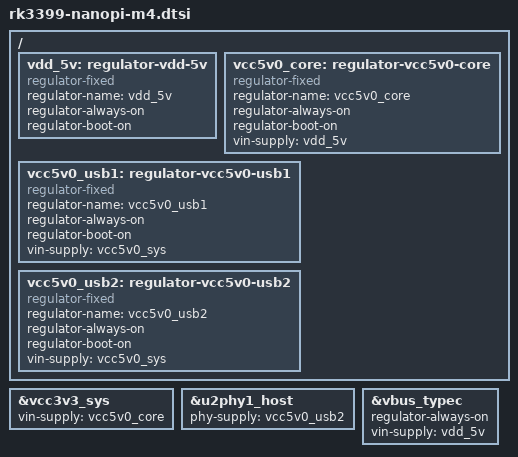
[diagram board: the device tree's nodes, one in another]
// SPDX-License-Identifier: (GPL-2.0+ OR MIT)
/*
 * FriendlyElec NanoPi M4 board device tree source
 *
 * Copyright (c) 2018 FriendlyElec Computer Tech. Co., Ltd.
 * (http://www.friendlyarm.com)
 *
 * Copyright (c) 2018 Collabora Ltd.
 * Copyright (c) 2019 Arm Ltd.
 */

/dts-v1/;

#include "rk3399-nanopi4.dtsi"

/ {
	vdd_5v: regulator-vdd-5v {
		compatible = "regulator-fixed";
		regulator-name = "vdd_5v";
		regulator-always-on;
		regulator-boot-on;
	};

	vcc5v0_core: regulator-vcc5v0-core {
		compatible = "regulator-fixed";
		regulator-name = "vcc5v0_core";
		regulator-always-on;
		regulator-boot-on;
		vin-supply = <&vdd_5v>;
	};

	vcc5v0_usb1: regulator-vcc5v0-usb1 {
		compatible = "regulator-fixed";
		regulator-name = "vcc5v0_usb1";
		regulator-always-on;
		regulator-boot-on;
		vin-supply = <&vcc5v0_sys>;
	};

	vcc5v0_usb2: regulator-vcc5v0-usb2 {
		compatible = "regulator-fixed";
		regulator-name = "vcc5v0_usb2";
		regulator-always-on;
		regulator-boot-on;
		vin-supply = <&vcc5v0_sys>;
	};
};

&vcc3v3_sys {
	vin-supply = <&vcc5v0_core>;
};

&u2phy1_host {
	phy-supply = <&vcc5v0_usb2>;
};

&vbus_typec {
	regulator-always-on;
	vin-supply = <&vdd_5v>;
};
